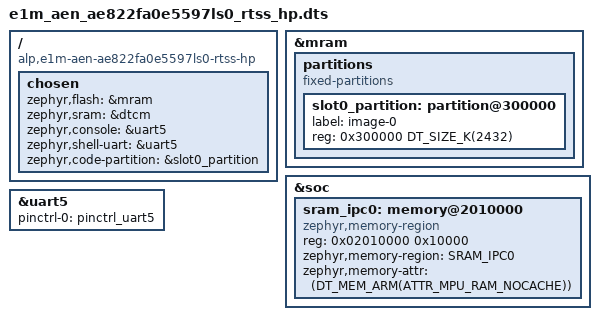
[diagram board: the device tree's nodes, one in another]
/*
 * Copyright (c) 2026 Alp Lab AB
 *
 * SPDX-License-Identifier: Apache-2.0
 */

/dts-v1/;

#include <alif/ensemble/ae822fa0e5597ls0.dtsi>
#include <alif/ensemble/common/ensemble_rtss_hp.dtsi>
#include <zephyr/dt-bindings/memory-attr/memory-attr-arm.h>
#include "e1m_aen-pinctrl.dtsi"

/ {
	compatible = "alp,e1m-aen-ae822fa0e5597ls0-rtss-hp";
	#address-cells = <1>;
	#size-cells = <1>;

	chosen {
		zephyr,flash = &mram;
		zephyr,sram = &dtcm;
		zephyr,console = &uart5;
		zephyr,shell-uart = &uart5;
		zephyr,code-partition = &slot0_partition;
	};
};

/*
 * MRAM split (mandatory -- this board's whole point is that both clusters' images
 * coexist in the same 5632 KB MRAM instead of each claiming all of it, which is what
 * upstream ensemble_e8_dk does and which would make flashing the second image
 * overwrite the first).
 *
 * Slots are assigned by RPMsg ROLE, not by cluster, to match where the resident
 * ATOC actually boots: the ATOC already on this SoM's bench unit boots M55-HE
 * (RTSS-HE) at MRAM-XIP address 0x80010000 (see docs/BENCH-DUALCORE.md section 1),
 * and RTSS-HE runs the RPMsg HOST role (apps/dualcore_host), not this cluster.
 * RTSS-HP (this file) runs the RPMsg REMOTE role (apps/dualcore_remote) and is
 * released from reset by the HOST at runtime -- it does not need to sit at the
 * resident ATOC's boot address, so it takes the other slot.
 *
 *   0x000000-0x00FFFF (  64 KB) : reserved -- this bench's slot0 convention starts the
 *                                 first image at MRAM base + 0x10000, and the Flow D
 *                                 helper ABORTS on a reset vector reading 8000xxxx
 *                                 (base-linked). Verified on E1M-AEN801 2026-07-30.
 *   0x010000-0x2FFFFF (3008 KB) : HOST image, rtss_he  (see e1m_aen_*_rtss_he.dts)
 *   0x300000-0x55FFFF (2432 KB) : REMOTE image, rtss_hp  (this file)
 *   0x560000-0x57FFFF ( 128 KB) : deliberately UNPARTITIONED headroom reserved for
 *                                 the Alif SETOOLS/ATOC application table (the tool
 *                                 that stitches multiple core images into one flashable
 *                                 image; it needs its own space outside both slot0s).
 */
&mram {
	partitions {
		compatible = "fixed-partitions";
		#address-cells = <1>;
		#size-cells = <1>;
		/*
		 * NO `ranges;` here -- deliberate, and it differs from upstream
		 * boards/alif/ensemble_e8_dk/ensemble_e8_dk_ae402fa0e5597le0_*.dts
		 * (which HAS it; the ae822fa0e5597ls0 variants correctly do not).
		 * With `ranges;` the partition reg is translated through mram's own
		 * ranges = <0x0 0x80000000 ...> into an ABSOLUTE address, so
		 * CONFIG_FLASH_LOAD_OFFSET becomes 0x80000000 and the linker then adds
		 * the MRAM base a second time -- the image links at 0x00000000 (ITCM
		 * base), not MRAM. Verified: rom_start VMA 00000000 with `ranges;`,
		 * VMA 80000000 without it.
		 */

		/*
		 * Starts at 0x300000, NOT 0x10000. This is the REMOTE role's slot,
		 * abutting the HOST (rtss_he) slot at 0x10000-0x2FFFFF -- the
		 * resident ATOC never boots this cluster directly, so it does not
		 * need the 8001xxxx reset-vector address the Flow D helper checks
		 * for. Ends at 0x560000, leaving 0x560000-0x57FFFF (128 KB) free
		 * for the Alif SETOOLS/ATOC application table.
		 */
		slot0_partition: partition@300000 {
			label = "image-0";
			reg = <0x300000 DT_SIZE_K(2432)>;
		};
	};
};

&soc {
	/*
	 * IPC shared-memory carve-out, inside sram0@2000000 (4 MB, see
	 * dts/arm/alif/ensemble/ae822fa0e5597ls0.dtsi). Neither rtss_hp nor rtss_he links
	 * its zephyr,sram here (both use &dtcm), so this carve-out never collides with
	 * either core's working RAM -- it exists solely for the OpenAMP vrings and the
	 * IPC payload the two cores exchange.
	 *
	 * ATTR_MPU_RAM_NOCACHE is load-bearing, not cosmetic: soc/alif/ensemble/common/soc.c's
	 * soc_reset_hook() unconditionally calls sys_cache_instr_enable() and
	 * sys_cache_data_enable() on every M55 core Zephyr boots on this SoC. Without this
	 * attribute the MPU would map this region cacheable and the two cores' private
	 * D-cache copies of the vrings would silently diverge, hanging IPC intermittently
	 * instead of failing loudly.
	 */
	sram_ipc0: memory@2010000 {
		compatible = "zephyr,memory-region", "mmio-sram";
		reg = <0x02010000 0x10000>;
		zephyr,memory-region = "SRAM_IPC0";
		zephyr,memory-attr = <(DT_MEM_ARM(ATTR_MPU_RAM_NOCACHE))>;
	};
};

&uart5 {
	status = "okay";
	pinctrl-0 = <&pinctrl_uart5>;
	pinctrl-names = "default";
};
